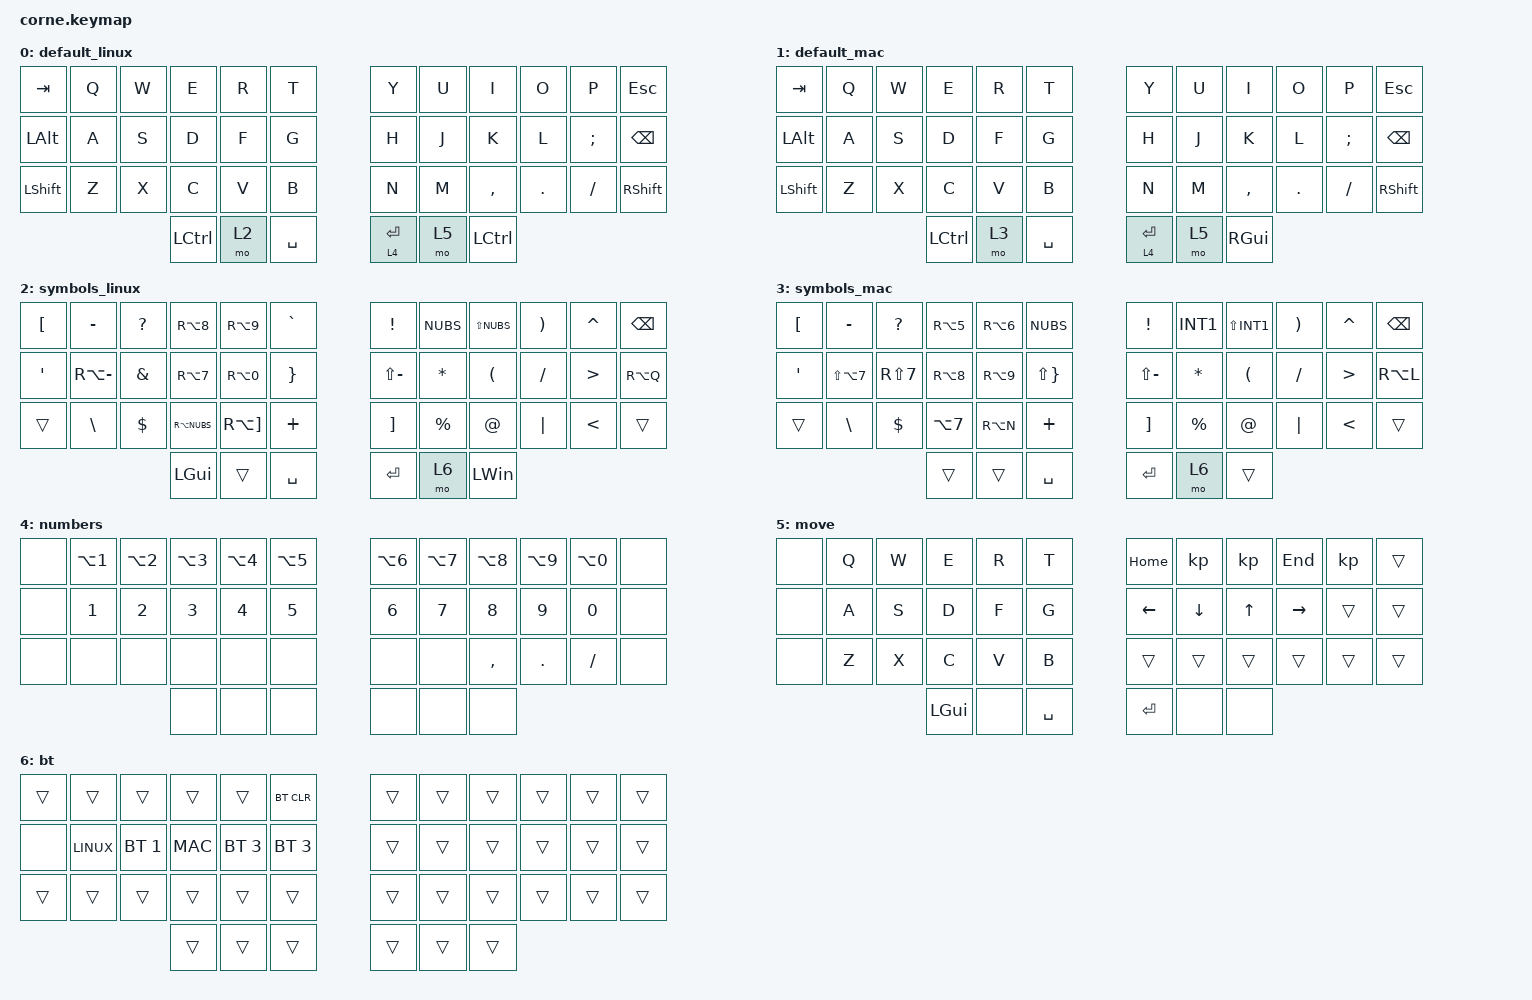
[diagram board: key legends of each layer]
/*
 * Copyright (c) 2020 The ZMK Contributors
 *
 * SPDX-License-Identifier: MIT
 */

#include <behaviors.dtsi>
#include <dt-bindings/zmk/bt.h>
#include <dt-bindings/zmk/keys.h>

/ {
    macros {
        MAC: MAC {
            compatible = "zmk,behavior-macro";
            label = "MAC";
            #binding-cells = <0>;
            bindings = <&macro_tap>, <&to 1>, <&macro_tap>, <&bt BT_SEL 2>;
        };
        LINUX: LINUX {
            compatible = "zmk,behavior-macro";
            label = "LINUX";
            #binding-cells = <0>;
            bindings = <&macro_tap>, <&to 0>, <&macro_tap>, <&bt BT_SEL 0>;
        };
    };

    keymap {
        compatible = "zmk,keymap";

        default_linux {
            bindings = <
&kp TAB    &kp Q  &kp W  &kp E      &kp R  &kp T        &kp Y        &kp U  &kp I      &kp O    &kp P     &kp ESCAPE
&kp LALT   &kp A  &kp S  &kp D      &kp F  &kp G        &kp H        &kp J  &kp K      &kp L    &kp SEMI  &kp BACKSPACE
&kp LSHFT  &kp Z  &kp X  &kp C      &kp V  &kp B        &kp N        &kp M  &kp COMMA  &kp DOT  &kp FSLH  &kp RIGHT_SHIFT
                         &kp LCTRL  &mo 2  &kp SPACE    &lt 4 ENTER  &mo 5  &kp LCTRL
            >;
        };

        default_mac {
            bindings = <
&kp TAB    &kp Q  &kp W  &kp E             &kp R  &kp T        &kp Y        &kp U  &kp I      &kp O    &kp P     &kp ESCAPE
&kp LALT   &kp A  &kp S  &kp D             &kp F  &kp G        &kp H        &kp J  &kp K      &kp L    &kp SEMI  &kp BACKSPACE
&kp LSHFT  &kp Z  &kp X  &kp C             &kp V  &kp B        &kp N        &kp M  &kp COMMA  &kp DOT  &kp FSLH  &kp RIGHT_SHIFT
                         &kp LEFT_CONTROL  &mo 3  &kp SPACE    &lt 4 ENTER  &mo 5  &kp RGUI
            >;
        };

        symbols_linux {
            bindings = <
&kp LEFT_BRACKET  &kp MINUS      &kp QUESTION   &kp RA(NUMBER_8)  &kp RA(NUMBER_9)       &kp GRAVE          &kp EXCL           &kp NUBS     &kp LS(NUBS)          &kp RPAR   &kp CARET         &kp BSPC
&kp SINGLE_QUOTE  &kp RA(MINUS)  &kp AMPERSAND  &kp RA(NUMBER_7)  &kp RA(NUMBER_0)       &kp RIGHT_BRACE    &kp LS(MINUS)      &kp ASTRK    &kp LEFT_PARENTHESIS  &kp SLASH  &kp GREATER_THAN  &kp RA(Q)
&trans            &kp BACKSLASH  &kp DOLLAR     &kp RA(NUBS)      &kp RA(RIGHT_BRACKET)  &kp PLUS           &kp RIGHT_BRACKET  &kp PERCENT  &kp AT                &kp PIPE   &kp LESS_THAN     &trans
                                                &kp LGUI          &trans                 &kp SPACE          &kp RET            &mo 6        &kp LEFT_WIN
            >;
        };

        symbols_mac {
            bindings = <
&kp LEFT_BRACKET  &kp MINUS             &kp QUESTION      &kp RA(NUMBER_5)  &kp RA(NUMBER_6)  &kp NUBS        &kp EXCL           &kp INT1     &kp LS(INT1)          &kp RPAR   &kp CARET         &kp BSPC
&kp SINGLE_QUOTE  &kp LS(LA(NUMBER_7))  &kp RS(NUMBER_7)  &kp RA(NUMBER_8)  &kp RA(N9)        &kp LS(RBRC)    &kp LS(MINUS)      &kp ASTRK    &kp LEFT_PARENTHESIS  &kp SLASH  &kp GREATER_THAN  &kp RA(L)
&trans            &kp BACKSLASH         &kp DOLLAR        &kp LA(NUMBER_7)  &kp RA(N)         &kp PLUS        &kp RIGHT_BRACKET  &kp PERCENT  &kp AT                &kp PIPE   &kp LESS_THAN     &trans
                                                          &trans            &trans            &kp SPACE       &kp RET            &mo 6        &trans
            >;
        };

        numbers {
            bindings = <
&none  &kp LA(NUMBER_1)  &kp LA(NUMBER_2)  &kp LA(NUMBER_3)  &kp LA(NUMBER_4)  &kp LA(NUMBER_5)    &kp LA(NUMBER_6)  &kp LA(NUMBER_7)  &kp LA(NUMBER_8)  &kp LA(NUMBER_9)  &kp LA(NUMBER_0)  &none
&none  &kp N1            &kp NUMBER_2      &kp NUMBER_3      &kp NUMBER_4      &kp NUMBER_5        &kp NUMBER_6      &kp NUMBER_7      &kp NUMBER_8      &kp NUMBER_9      &kp NUMBER_0      &none
&none  &none             &none             &none             &none             &none               &none             &none             &kp COMMA         &kp DOT           &kp SLASH         &none
                                           &none             &none             &none               &none             &none             &none
            >;
        };

        move {
            bindings = <
&none  &kp Q  &kp W  &kp E     &kp R  &kp T        &kp HOME  &kp       &kp     &kp END    &kp     &trans
&none  &kp A  &kp S  &kp D     &kp F  &kp G        &kp LEFT  &kp DOWN  &kp UP  &kp RIGHT  &trans  &trans
&none  &kp Z  &kp X  &kp C     &kp V  &kp B        &trans    &trans    &trans  &trans     &trans  &trans
                     &kp LGUI  &none  &kp SPACE    &kp RET   &none     &none
            >;
        };

        bt {
            bindings = <
&trans  &trans  &trans        &trans  &trans        &bt BT_CLR      &trans  &trans  &trans  &trans  &trans  &trans
&none   &LINUX  &bt BT_SEL 1  &MAC    &bt BT_SEL 3  &bt BT_SEL 3    &trans  &trans  &trans  &trans  &trans  &trans
&trans  &trans  &trans        &trans  &trans        &trans          &trans  &trans  &trans  &trans  &trans  &trans
                              &trans  &trans        &trans          &trans  &trans  &trans
            >;
        };
    };
};
